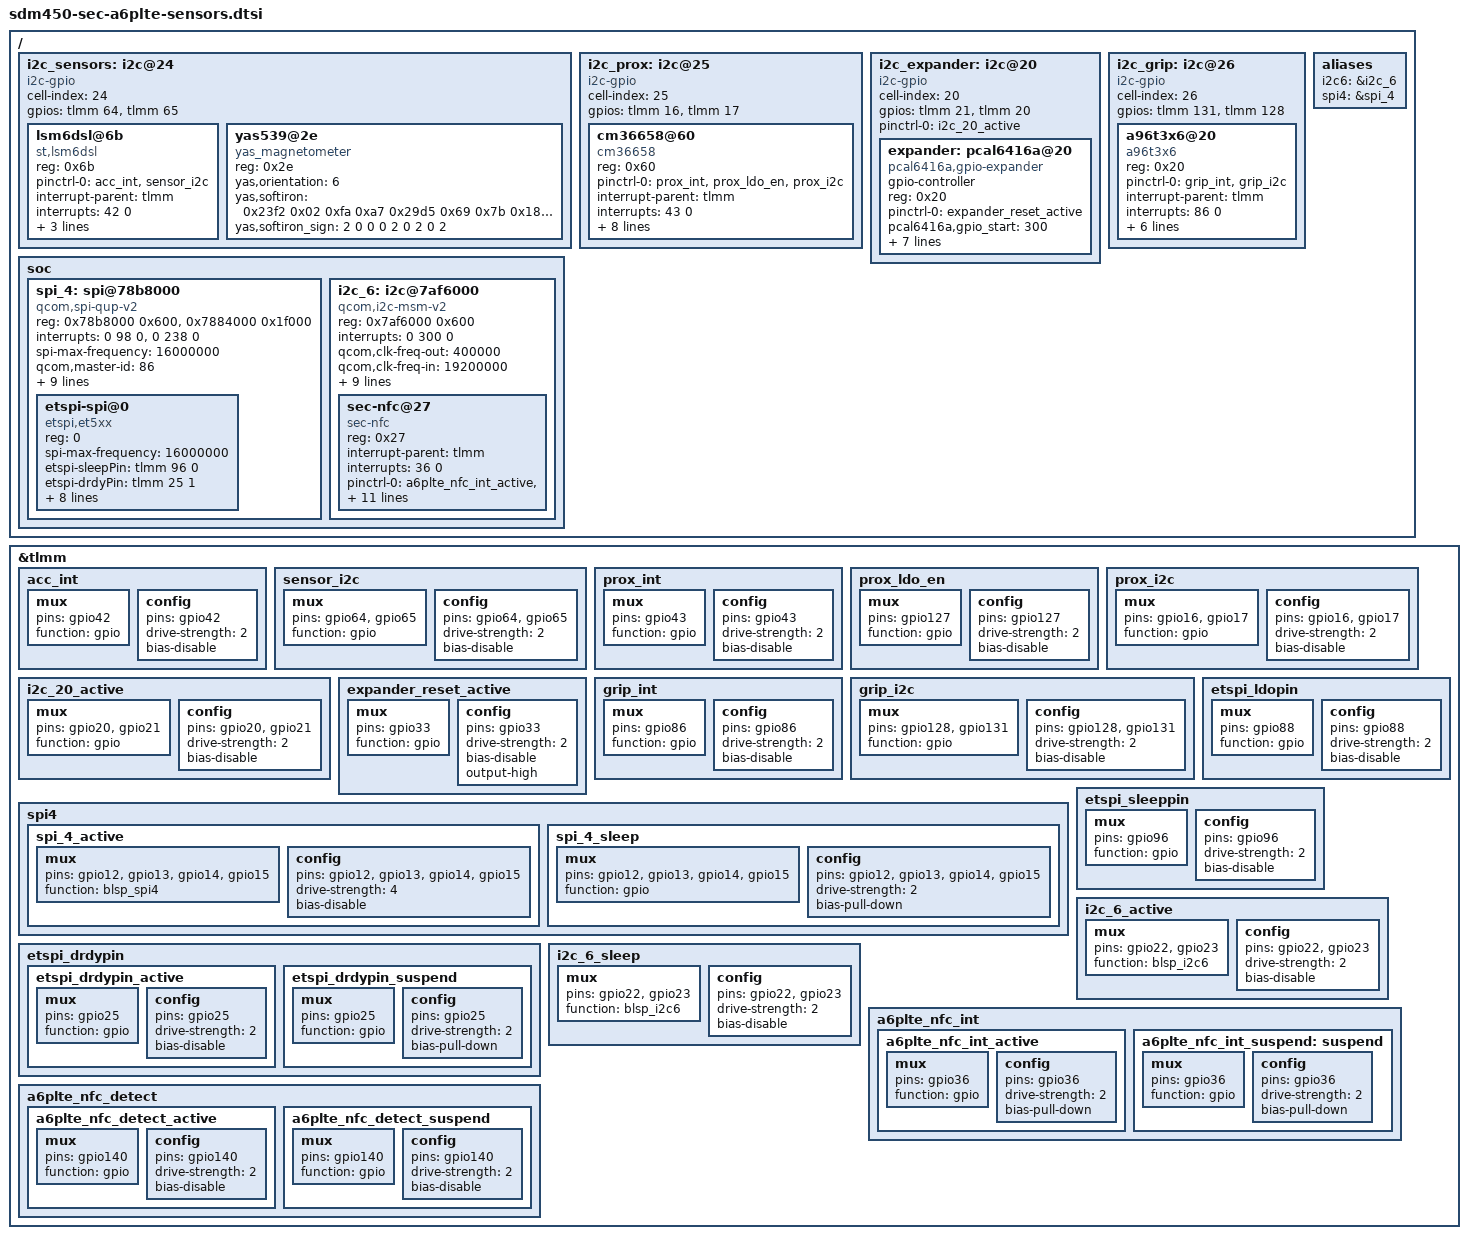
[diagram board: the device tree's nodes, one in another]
// Accelerometer/gyroscope (LSM6DSL), magnetometer (YAS539) and proximity/light
// sensor (CM36658) of the Samsung A6+, ported from the stock DT.

&tlmm {
	acc_int: acc_int {
		mux {
			pins = "gpio42";
			function = "gpio";
		};
		config {
			pins = "gpio42";
			drive-strength = <2>;
			bias-disable;
		};
	};

	sensor_i2c: sensor_i2c {
		mux {
			pins = "gpio64", "gpio65";
			function = "gpio";
		};
		config {
			pins = "gpio64", "gpio65";
			drive-strength = <2>;
			bias-disable;
		};
	};

	prox_int: prox_int {
		mux {
			pins = "gpio43";
			function = "gpio";
		};
		config {
			pins = "gpio43";
			drive-strength = <2>;
			bias-disable;
		};
	};

	prox_ldo_en: prox_ldo_en {
		mux {
			pins = "gpio127";
			function = "gpio";
		};
		config {
			pins = "gpio127";
			drive-strength = <2>;
			bias-disable;
		};
	};

	prox_i2c: prox_i2c {
		mux {
			pins = "gpio16", "gpio17";
			function = "gpio";
		};
		config {
			pins = "gpio16", "gpio17";
			drive-strength = <2>;
			bias-disable;
		};
	};
};

/ {
	i2c_sensors: i2c@24 {
		cell-index = <24>;
		compatible = "i2c-gpio";
		gpios = <&tlmm 64 0 &tlmm 65 0>;
		#address-cells = <1>;
		#size-cells = <0>;

		lsm6dsl@6b {
			compatible = "st,lsm6dsl";
			reg = <0x6b>;
			pinctrl-names = "default";
			pinctrl-0 = <&acc_int &sensor_i2c>;
			interrupt-parent = <&tlmm>;
			interrupts = <42 0>;
			st,orientation = <2 1 1 1 2 1 1 1 2>;
			st,drdy-int-pin = <1>;
			st,irq_gpio = <&tlmm 42 0>;
		};

		yas539@2e {
			compatible = "yas_magnetometer";
			reg = <0x2e>;
			yas,orientation = <6>;
			yas,softiron = <0x23f2 0x02 0xfa 0xa7 0x29d5 0x69 0x7b 0x188 0x29a7>;
			yas,softiron_sign = <2 0 0 0 2 0 2 0 2>;
		};
	};

	i2c_prox: i2c@25 {
		cell-index = <25>;
		compatible = "i2c-gpio";
		gpios = <&tlmm 16 0 &tlmm 17 0>;
		#address-cells = <1>;
		#size-cells = <0>;

		cm36658@60 {
			compatible = "cm36658";
			reg = <0x60>;
			pinctrl-names = "default";
			pinctrl-0 = <&prox_int &prox_ldo_en &prox_i2c>;
			interrupt-parent = <&tlmm>;
			interrupts = <43 0>;
			cm36658,irq_pin = <&tlmm 43 0>;
			cm36658,led_ldo_pin = <&tlmm 127 0>;
			cm36658,thresh_high = <0x82>;
			cm36658,thresh_low = <0x5a>;
			cm36658,thresh_detect_high = <0xfa0>;
			cm36658,thresh_detect_low = <0x258>;
			cm36658,ps_conf1_reg = <0xc970>;
			cm36658,ps_conf3_reg = <0x8108>;
		};
	};
};

// PCAL6416A GPIO expander (stock i2c@... on gpio 21/20). Its init drives
// pin 6 (gpio 306) high; the sensors do not ACK without it.
&tlmm {
	i2c_20_active: i2c_20_active {
		mux {
			pins = "gpio20", "gpio21";
			function = "gpio";
		};
		config {
			pins = "gpio20", "gpio21";
			drive-strength = <2>;
			bias-disable;
		};
	};

	expander_reset_active: expander_reset_active {
		mux {
			pins = "gpio33";
			function = "gpio";
		};
		config {
			pins = "gpio33";
			drive-strength = <2>;
			bias-disable;
			output-high;
		};
	};
};

/ {
	i2c_expander: i2c@20 {
		cell-index = <20>;
		compatible = "i2c-gpio";
		gpios = <&tlmm 21 0 &tlmm 20 0>;
		#address-cells = <1>;
		#size-cells = <0>;
		pinctrl-names = "default";
		pinctrl-0 = <&i2c_20_active>;

		expander: pcal6416a@20 {
			compatible = "pcal6416a,gpio-expander";
			gpio-controller;
			#gpio-cells = <2>;
			reg = <0x20>;
			pinctrl-names = "expander_reset_setting";
			pinctrl-0 = <&expander_reset_active>;
			pcal6416a,gpio_start = <300>;
			pcal6416a,ngpio = <16>;
			pcal6416a,reset-gpio = <&tlmm 33 0>;
			pcal6416a,vdd-supply = <&pm8953_l5>;
			pcal6416a,support_initialize = <1>;
			pcal6416a,config = <0xf89f>;
			pcal6416a,data_out = <0x40>;
			pcal6416a,pull_reg = <0x100400>;
		};
	};
};

// Grip sensor (Abov A96T346), stock i2c@26 on TLMM 131 (SDA) / 128 (SCL).
&tlmm {
	grip_int: grip_int {
		mux {
			pins = "gpio86";
			function = "gpio";
		};
		config {
			pins = "gpio86";
			drive-strength = <2>;
			bias-disable;
		};
	};

	grip_i2c: grip_i2c {
		mux {
			pins = "gpio128", "gpio131";
			function = "gpio";
		};
		config {
			pins = "gpio128", "gpio131";
			drive-strength = <2>;
			bias-disable;
		};
	};
};

/ {
	i2c_grip: i2c@26 {
		cell-index = <26>;
		compatible = "i2c-gpio";
		gpios = <&tlmm 131 0 &tlmm 128 0>;
		#address-cells = <1>;
		#size-cells = <0>;

		a96t3x6@20 {
			compatible = "a96t3x6";
			reg = <0x20>;
			pinctrl-names = "default";
			pinctrl-0 = <&grip_int &grip_i2c>;
			interrupt-parent = <&tlmm>;
			interrupts = <86 0>;
			a96t3x6,irq_gpio = <&tlmm 86 0>;
			a96t3x6,ldo_en = <&tlmm 87 0>;
			a96t3x6,fw_path = "abov/a96t346_j8plte.fw";
			a96t3x6,chipid = "A96T346";
			a96t3x6,firmup_cmd = <0x38>;
			a96t3x6,earjack_noise = <0x01>;
		};
	};
};

&tlmm {
	spi4 {
		spi_4_active: spi_4_active {
			mux {
				pins = "gpio12", "gpio13", "gpio14", "gpio15";
				function = "blsp_spi4";
			};
			config {
				pins = "gpio12", "gpio13", "gpio14", "gpio15";
				drive-strength = <4>;
				bias-disable;
			};
		};
		spi_4_sleep: spi_4_sleep {
			mux {
				pins = "gpio12", "gpio13", "gpio14", "gpio15";
				function = "gpio";
			};
			config {
				pins = "gpio12", "gpio13", "gpio14", "gpio15";
				drive-strength = <2>;
				bias-pull-down;
			};
		};
	};

	etspi_drdypin {
		etspi_drdypin_active: etspi_drdypin_active {
			mux { pins = "gpio25"; function = "gpio"; };
			config { pins = "gpio25"; drive-strength = <2>; bias-disable; };
		};
		etspi_drdypin_suspend: etspi_drdypin_suspend {
			mux { pins = "gpio25"; function = "gpio"; };
			config { pins = "gpio25"; drive-strength = <2>; bias-pull-down; };
		};
	};

	etspi_ldopin: etspi_ldopin {
		mux { pins = "gpio88"; function = "gpio"; };
		config { pins = "gpio88"; drive-strength = <2>; bias-disable; };
	};

	etspi_sleeppin: etspi_sleeppin {
		mux { pins = "gpio96"; function = "gpio"; };
		config { pins = "gpio96"; drive-strength = <2>; bias-disable; };
	};
};

/ {
	soc {
		spi_4: spi@78b8000 { /* BLSP1 QUP4 */
			compatible = "qcom,spi-qup-v2";
			#address-cells = <1>;
			#size-cells = <0>;
			reg-names = "spi_physical", "spi_bam_physical";
			reg = <0x78b8000 0x600>, <0x7884000 0x1f000>;
			interrupt-names = "spi_irq", "spi_bam_irq";
			interrupts = <0 98 0>, <0 238 0>;
			spi-max-frequency = <16000000>;
			qcom,master-id = <86>;
			qcom,ver-reg-exists;
			qcom,use-pinctrl;
			qcom,use-bam;
			qcom,bam-consumer-pipe-index = <10>;
			qcom,bam-producer-pipe-index = <11>;
			pinctrl-names = "spi_default", "spi_sleep";
			pinctrl-0 = <&spi_4_active>;
			pinctrl-1 = <&spi_4_sleep>;
			clock-names = "iface_clk", "core_clk";
			clocks = <&clock_gcc clk_gcc_blsp1_ahb_clk>,
				 <&clock_gcc clk_gcc_blsp1_qup4_spi_apps_clk>;
			status = "ok";

			etspi-spi@0 {
				compatible = "etspi,et5xx";
				reg = <0>;
				spi-max-frequency = <16000000>;
				etspi-sleepPin = <&tlmm 96 0>;
				etspi-drdyPin = <&tlmm 25 1>;
				etspi-ldoPin = <&tlmm 88 0>;
				etspi-min_cpufreq_limit = <2000000>;
				etspi-orient = <0>;
				etspi-chipid = "ET516";
				pinctrl-names = "default", "sleep", "idle";
				pinctrl-0 = <&etspi_drdypin_suspend &etspi_ldopin &etspi_sleeppin>;
				pinctrl-1 = <&etspi_drdypin_suspend>;
				pinctrl-2 = <&etspi_drdypin_active>;
			};
		};
	};
};

&tlmm {
	i2c_6_active: i2c_6_active {
		mux { pins = "gpio22", "gpio23"; function = "blsp_i2c6"; };
		config { pins = "gpio22", "gpio23"; drive-strength = <2>; bias-disable; };
	};
	i2c_6_sleep: i2c_6_sleep {
		mux { pins = "gpio22", "gpio23"; function = "blsp_i2c6"; };
		config { pins = "gpio22", "gpio23"; drive-strength = <2>; bias-disable; };
	};

	a6plte_nfc_int {
		a6plte_nfc_int_active: a6plte_nfc_int_active {
			mux { pins = "gpio36"; function = "gpio"; };
			config { pins = "gpio36"; drive-strength = <2>; bias-pull-down; };
		};
		a6plte_nfc_int_suspend: suspend {
			mux { pins = "gpio36"; function = "gpio"; };
			config { pins = "gpio36"; drive-strength = <2>; bias-pull-down; };
		};
	};
	a6plte_nfc_detect {
		a6plte_nfc_detect_active: a6plte_nfc_detect_active {
			mux { pins = "gpio140"; function = "gpio"; };
			config { pins = "gpio140"; drive-strength = <2>; bias-disable; };
		};
		a6plte_nfc_detect_suspend: a6plte_nfc_detect_suspend {
			mux { pins = "gpio140"; function = "gpio"; };
			config { pins = "gpio140"; drive-strength = <2>; bias-disable; };
		};
	};
};

/ {
	soc {
		i2c_6: i2c@7af6000 { /* BLSP2 QUP2 */
			compatible = "qcom,i2c-msm-v2";
			#address-cells = <1>;
			#size-cells = <0>;
			reg-names = "qup_phys_addr";
			reg = <0x7af6000 0x600>;
			interrupt-names = "qup_irq";
			interrupts = <0 300 0>;
			qcom,clk-freq-out = <400000>;
			qcom,clk-freq-in = <19200000>;
			clock-names = "iface_clk", "core_clk";
			clocks = <&clock_gcc clk_gcc_blsp2_ahb_clk>,
				 <&clock_gcc clk_gcc_blsp2_qup2_i2c_apps_clk>;
			pinctrl-names = "i2c_active", "i2c_sleep";
			pinctrl-0 = <&i2c_6_active>;
			pinctrl-1 = <&i2c_6_sleep>;
			qcom,noise-rjct-scl = <0>;
			qcom,noise-rjct-sda = <0>;
			qcom,master-id = <84>;
			dmas = <&dma_blsp2 6 64 0x20000020 0x20>,
			       <&dma_blsp2 7 32 0x20000020 0x20>;
			dma-names = "tx", "rx";
			status = "ok";

			sec-nfc@27 {
				compatible = "sec-nfc";
				reg = <0x27>;
				interrupt-parent = <&tlmm>;
				interrupts = <36 0>;
				pinctrl-names = "default", "sleep";
				pinctrl-0 = <&a6plte_nfc_int_active &a6plte_nfc_detect_active>;
				pinctrl-1 = <&a6plte_nfc_int_suspend &a6plte_nfc_detect_suspend>;
				sec-nfc,det-gpio = <&tlmm 140 0>;
				sec-nfc,ven-gpio = <&expander 9 0>;
				sec-nfc,firm-gpio = <&expander 10 0>;
				sec-nfc,irq-gpio = <&tlmm 36 0>;
				sec-nfc,pvdd_en = <&expander 8 0>;
				sec-nfc,nfc_pm_clk;
				clock-names = "rf_clk";
				clocks = <&clock_gcc clk_bb_clk2_pin>;
				qcom,clk-src = "BBCLK2";
			};
		};
	};
};

/ {
	aliases {
		i2c6 = &i2c_6;
		spi4 = &spi_4;
	};
};
